# CEC1712H_N2_SX register map
Vendor: Microchip
Registers are 32-bit, read-write, reset 0x0 unless marked. A register's access mark holds for its fields unless they carry their own. Addresses are absolute, and some are shared; only a register's first bit layout is shown; [hi:lo] are bit positions.

## TIMER16_1
0x40000C20 CNT
0x40000C24 PRLD
0x40000C28 STS
  [0] EVT_INT — This is the interrupt status that fires when the timer reaches its limit. This is the interrupt status that fires when the timer reaches its limit. This may be level or a self clearing signal cycle pulse, based on the AUTO_RESTART bit in the Timer. Control Register. If the timer is set to automatically restart, it will provide a pulse, otherwise a level is provided.(R/WC)
0x40000C2C IEN
  [0] EN — This is the interrupt enable for the status EVENT_INTERRUPT bit in the Timer Status Register.
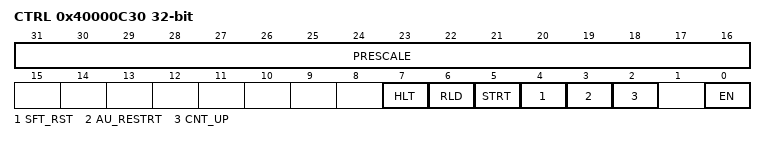
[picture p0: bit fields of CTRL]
0x40000C30 CTRL
  [31:16] PRESCALE — This is used to divide down the system clock through clock enables to lower the power consumption of the block and allow slow timers. Updating this value during operation may result in erroneous clock enable pulses until the clock divider restarts. The number of clocks per clock enable pulse is (Value + 1); a setting of 0 runs at the full clock speed, while a setting of 1 runs at half speed.
  [7] HLT — This is a halt bit. This will halt the timer as long as it is active. Once the halt is inactive, the timer will start from where it left off. 1=Timer is halted. It stops counting. The clock divider will also be reset. 0=Timer runs normally.
  [6] RLD — This bit reloads the counter without interrupting it operation. This will not function if the timer has already completed (when the START bit in this register is '0'). This is used to periodically prevent the timer from firing when an event occurs. Usage while the timer is off may result in erroneous behaviour.
  [5] STRT — This bit triggers the timer counter. The counter will operate until it hits its terminating condition. This will clear this bit. It should be noted that when operating in restart mode, there is no terminating condition for the counter, so this bit will never clear. Clearing this bit will halt the timer counter.
  [4] SFT_RST — This is a soft reset. This is self clearing 1 cycle after it is written. Firmware does not need to wait before reconfiguring the Basic Timer following soft reset.
  [3] AU_RESTRT — This will select the action taken upon completing a count. 1=The counter will automatically restart the count, using the contents of the Timer Preload Register to load the Timer Count Register. The interrupt will be set in edge mode. 0=The counter will simply enter a done state and wait for further control inputs. The interrupt will be set in level mode.
  [2] CNT_UP — This selects the counter direction. When the counter in incrementing the counter will saturate and trigger the event when it reaches all F's. When the counter is decrementing the counter will saturate when it reaches 0h. 1=The counter will increment; 0=The counter will decrement
  [0] EN — This enables the block for operation. 1=This block will function normally; 0=This block will gate its clock and go into its lowest power state

## TIMER32_0
0x40000C80 CNT
0x40000C84 PRLD
0x40000C88 STS
  [0] EVT_INT — This is the interrupt status that fires when the timer reaches its limit. This is the interrupt status that fires when the timer reaches its limit. This may be level or a self clearing signal cycle pulse, based on the AUTO_RESTART bit in the Timer. Control Register. If the timer is set to automatically restart, it will provide a pulse, otherwise a level is provided.(R/WC)
0x40000C8C IEN
  [0] EN — This is the interrupt enable for the status EVENT_INTERRUPT bit in the Timer Status Register.
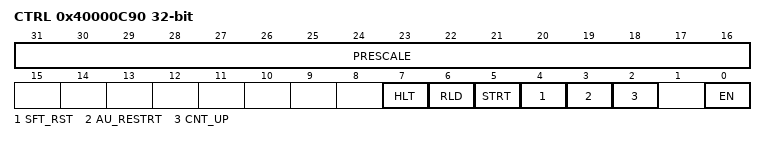
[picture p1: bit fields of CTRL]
0x40000C90 CTRL
  [31:16] PRESCALE — This is used to divide down the system clock through clock enables to lower the power consumption of the block and allow slow timers. Updating this value during operation may result in erroneous clock enable pulses until the clock divider restarts. The number of clocks per clock enable pulse is (Value + 1); a setting of 0 runs at the full clock speed, while a setting of 1 runs at half speed.
  [7] HLT — This is a halt bit. This will halt the timer as long as it is active. Once the halt is inactive, the timer will start from where it left off. 1=Timer is halted. It stops counting. The clock divider will also be reset. 0=Timer runs normally.
  [6] RLD — This bit reloads the counter without interrupting it operation. This will not function if the timer has already completed (when the START bit in this register is '0'). This is used to periodically prevent the timer from firing when an event occurs. Usage while the timer is off may result in erroneous behaviour.
  [5] STRT — This bit triggers the timer counter. The counter will operate until it hits its terminating condition. This will clear this bit. It should be noted that when operating in restart mode, there is no terminating condition for the counter, so this bit will never clear. Clearing this bit will halt the timer counter.
  [4] SFT_RST — This is a soft reset. This is self clearing 1 cycle after it is written. Firmware does not need to wait before reconfiguring the Basic Timer following soft reset.
  [3] AU_RESTRT — This will select the action taken upon completing a count. 1=The counter will automatically restart the count, using the contents of the Timer Preload Register to load the Timer Count Register. The interrupt will be set in edge mode. 0=The counter will simply enter a done state and wait for further control inputs. The interrupt will be set in level mode.
  [2] CNT_UP — This selects the counter direction. When the counter in incrementing the counter will saturate and trigger the event when it reaches all F's. When the counter is decrementing the counter will saturate when it reaches 0h. 1=The counter will increment; 0=The counter will decrement
  [0] EN — This enables the block for operation. 1=This block will function normally; 0=This block will gate its clock and go into its lowest power state
